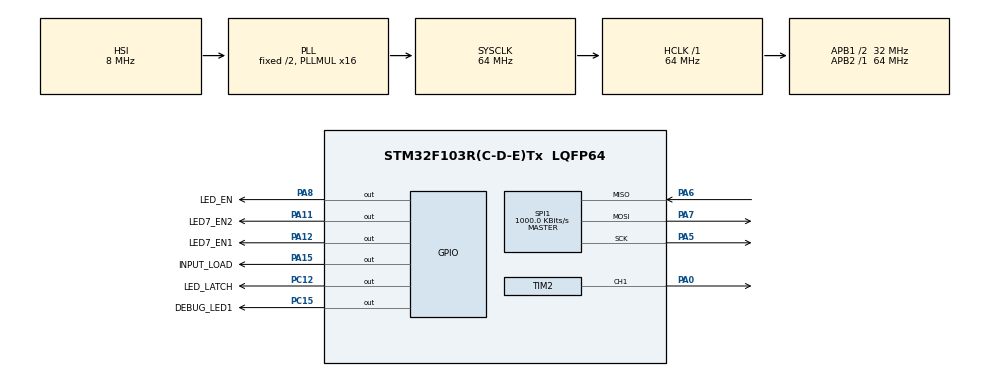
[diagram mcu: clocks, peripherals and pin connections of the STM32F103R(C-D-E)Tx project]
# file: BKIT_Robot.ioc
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Mcu.Family=STM32F1
Mcu.Name=STM32F103R(C-D-E)Tx
Mcu.Package=LQFP64
NVIC.PriorityGroup=NVIC_PRIORITYGROUP_4
NVIC.TIM3_IRQn=true\:0\:0\:false\:false\:true\:true\:true\:true
PA0-WKUP.Signal=S_TIM2_CH1_ETR
PA11.GPIO_Label=LED7_EN2
PA11.Signal=GPIO_Output
PA12.GPIO_Label=LED7_EN1
PA12.Signal=GPIO_Output
PA13.Mode=Serial_Wire
PA13.Signal=SYS_JTMS-SWDIO
PA14.Mode=Serial_Wire
PA14.Signal=SYS_JTCK-SWCLK
PA15.GPIO_Label=INPUT_LOAD
PA15.Signal=GPIO_Output
PA5.Mode=Full_Duplex_Master
PA5.Signal=SPI1_SCK
PA6.Mode=Full_Duplex_Master
PA6.Signal=SPI1_MISO
PA7.Mode=Full_Duplex_Master
PA7.Signal=SPI1_MOSI
PA8.GPIO_Label=LED_EN
PA8.Signal=GPIO_Output
PC12.GPIO_Label=LED_LATCH
PC12.Signal=GPIO_Output
PC15-OSC32_OUT.GPIO_Label=DEBUG_LED1
PC15-OSC32_OUT.Signal=GPIO_Output
ProjectManager.HeapSize=0x200
ProjectManager.StackSize=0x400
ProjectManager.TargetToolchain=STM32CubeIDE
RCC.AHBFreq_Value=64000000
RCC.APB1CLKDivider=RCC_HCLK_DIV2
RCC.APB1Freq_Value=32000000
RCC.APB1TimFreq_Value=64000000
RCC.APB2Freq_Value=64000000
RCC.APB2TimFreq_Value=64000000
RCC.HCLKFreq_Value=64000000
RCC.PLLMUL=RCC_PLL_MUL16
RCC.SYSCLKFreq_VALUE=64000000
RCC.SYSCLKSource=RCC_SYSCLKSOURCE_PLLCLK
RCC.USBFreq_Value=64000000
SH.S_TIM2_CH1_ETR.0=TIM2_CH1,PWM Generation1 CH1
SPI1.BaudRatePrescaler=SPI_BAUDRATEPRESCALER_64
SPI1.CalculateBaudRate=1000.0 KBits/s
SPI1.Direction=SPI_DIRECTION_2LINES
SPI1.Mode=SPI_MODE_MASTER
SPI1.VirtualType=VM_MASTER
TIM2.AutoReloadPreload=TIM_AUTORELOAD_PRELOAD_ENABLE
TIM2.Channel-PWM\ Generation1\ CH1=TIM_CHANNEL_1
TIM2.Period=100
TIM2.Prescaler=639
TIM3.AutoReloadPreload=TIM_AUTORELOAD_PRELOAD_ENABLE
TIM3.Period=100
TIM3.Prescaler=639
VP_TIM2_VS_ClockSourceINT.Mode=Internal
VP_TIM3_VS_ClockSourceINT.Mode=Internal
board=custom

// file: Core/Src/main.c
/* USER CODE BEGIN Header */
/**
  ******************************************************************************
  * @file           : main.c
  * @brief          : Main program body
  ******************************************************************************
  * @attention
  *
  * Copyright (c) 2025 STMicroelectronics.
  * All rights reserved.
  *
  * This software is licensed under terms that can be found in the LICENSE file
  * in the root directory of this software component.
  * If no LICENSE file comes with this software, it is provided AS-IS.
  *
  ******************************************************************************
  */
/* USER CODE END Header */
#include "main.h"
#include "spi.h"
#include "tim.h"
#include "gpio.h"

/* USER CODE BEGIN Includes */
#include "led7seg.h"

/* USER CODE END Includes */

void SystemClock_Config(void);

int main(void)
{

  /* MCU Configuration--------------------------------------------------------*/

  /* Reset of all peripherals, Initializes the Flash interface and the Systick. */
  HAL_Init();

  /* Configure the system clock */
  SystemClock_Config();

  /* Initialize all configured peripherals */
  MX_GPIO_Init();
  MX_TIM2_Init();
  MX_SPI1_Init();
  MX_TIM3_Init();
  /* USER CODE BEGIN 2 */
  LED_init();

  /* USER CODE END 2 */

  /* Infinite loop */
  while (1)
  {

    /* USER CODE BEGIN 3 */
	  test_led_control();

  }
  /* USER CODE END 3 */
}

void SystemClock_Config(void)
{
  RCC_OscInitTypeDef RCC_OscInitStruct = {0};
  RCC_ClkInitTypeDef RCC_ClkInitStruct = {0};

  /** Initializes the RCC Oscillators according to the specified parameters
  * in the RCC_OscInitTypeDef structure.
  */
  RCC_OscInitStruct.OscillatorType = RCC_OSCILLATORTYPE_HSI;
  RCC_OscInitStruct.HSIState = RCC_HSI_ON;
  RCC_OscInitStruct.HSICalibrationValue = RCC_HSICALIBRATION_DEFAULT;
  RCC_OscInitStruct.PLL.PLLState = RCC_PLL_ON;
  RCC_OscInitStruct.PLL.PLLSource = RCC_PLLSOURCE_HSI_DIV2;
  RCC_OscInitStruct.PLL.PLLMUL = RCC_PLL_MUL16;
  if (HAL_RCC_OscConfig(&RCC_OscInitStruct) != HAL_OK)
  {
    Error_Handler();
  }

  /** Initializes the CPU, AHB and APB buses clocks
  */
  RCC_ClkInitStruct.ClockType = RCC_CLOCKTYPE_HCLK|RCC_CLOCKTYPE_SYSCLK
                              |RCC_CLOCKTYPE_PCLK1|RCC_CLOCKTYPE_PCLK2;
  RCC_ClkInitStruct.SYSCLKSource = RCC_SYSCLKSOURCE_PLLCLK;
  RCC_ClkInitStruct.AHBCLKDivider = RCC_SYSCLK_DIV1;
  RCC_ClkInitStruct.APB1CLKDivider = RCC_HCLK_DIV2;
  RCC_ClkInitStruct.APB2CLKDivider = RCC_HCLK_DIV1;

  if (HAL_RCC_ClockConfig(&RCC_ClkInitStruct, FLASH_LATENCY_2) != HAL_OK)
  {
    Error_Handler();
  }
}

void Error_Handler(void)
{
  __disable_irq();
  while (1)
  {
  }
}
